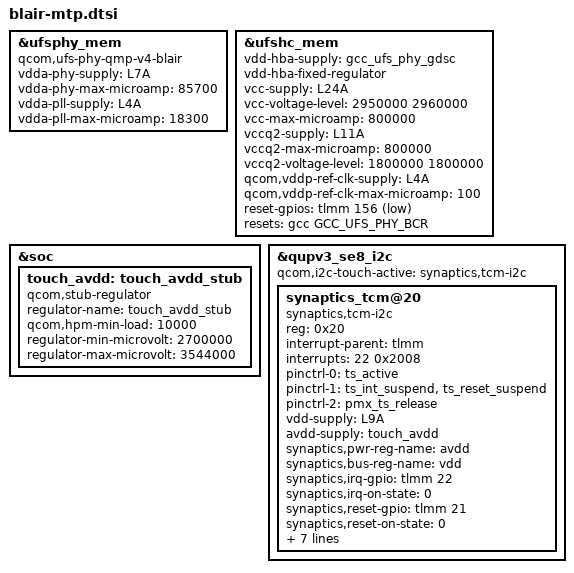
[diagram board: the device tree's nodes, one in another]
#include <dt-bindings/gpio/gpio.h>
#include <dt-bindings/clock/qcom,gcc-blair.h>

&ufsphy_mem {
	compatible = "qcom,ufs-phy-qmp-v4-blair";

	/* VDDA_UFS_CORE */
	vdda-phy-supply = <&L7A>;
	vdda-phy-max-microamp = <85700>;

	/* VDDA_UFS_0_1P2 */
	vdda-pll-supply = <&L4A>;
	vdda-pll-max-microamp = <18300>;

	status = "ok";
};

&ufshc_mem {
	vdd-hba-supply = <&gcc_ufs_phy_gdsc>;
	vdd-hba-fixed-regulator;

	vcc-supply = <&L24A>;
	vcc-voltage-level = <2950000 2960000>;
	vcc-max-microamp = <800000>;

	vccq2-supply = <&L11A>;
	vccq2-max-microamp = <800000>;
	vccq2-voltage-level = <1800000 1800000>;

	/* VDD_PX10 is voted for the ufs_reset_n */
	qcom,vddp-ref-clk-supply = <&L4A>;
	qcom,vddp-ref-clk-max-microamp = <100>;

	reset-gpios = <&tlmm 156 GPIO_ACTIVE_LOW>;
	resets = <&gcc GCC_UFS_PHY_BCR>;
	reset-names = "rst";

	status = "ok";
};

&soc {
	touch_avdd: touch_avdd_stub {
		/*
		 * Touch eLDO controlled by gpio#53 is always ON.
		 * Using dummy regulator.
		 */
		compatible = "qcom,stub-regulator";
		regulator-name = "touch_avdd_stub";
		qcom,hpm-min-load = <10000>;
		regulator-min-microvolt = <2700000>;
		regulator-max-microvolt = <3544000>;
	};
};

&qupv3_se8_i2c {
	#address-cells = <1>;
	#size-cells = <0>;
	status = "okay";
	qcom,i2c-touch-active= "synaptics,tcm-i2c";

	synaptics_tcm@20 {
		compatible = "synaptics,tcm-i2c";
		reg = <0x20>;
		interrupt-parent = <&tlmm>;
		interrupts = <22 0x2008>;
		pinctrl-names = "pmx_ts_active","pmx_ts_suspend",
					"pmx_ts_release";
		pinctrl-0 = <&ts_active>;
		pinctrl-1 = <&ts_int_suspend &ts_reset_suspend>;
		pinctrl-2 = <&pmx_ts_release>;
		vdd-supply = <&L9A>;
		avdd-supply = <&touch_avdd>;
		synaptics,pwr-reg-name = "avdd";
		synaptics,bus-reg-name = "vdd";
		synaptics,irq-gpio = <&tlmm 22 0x2008>;
		synaptics,irq-on-state = <0>;
		synaptics,reset-gpio = <&tlmm 21 0x00>;
		synaptics,reset-on-state = <0>;
		synaptics,reset-active-ms = <20>;
		synaptics,reset-delay-ms = <200>;
		synaptics,power-delay-ms = <200>;
		synaptics,ubl-i2c-addr = <0x20>;
		synaptics,extend_report;
		synaptics,firmware-name = "synaptics_firmware.img";
	};
};
